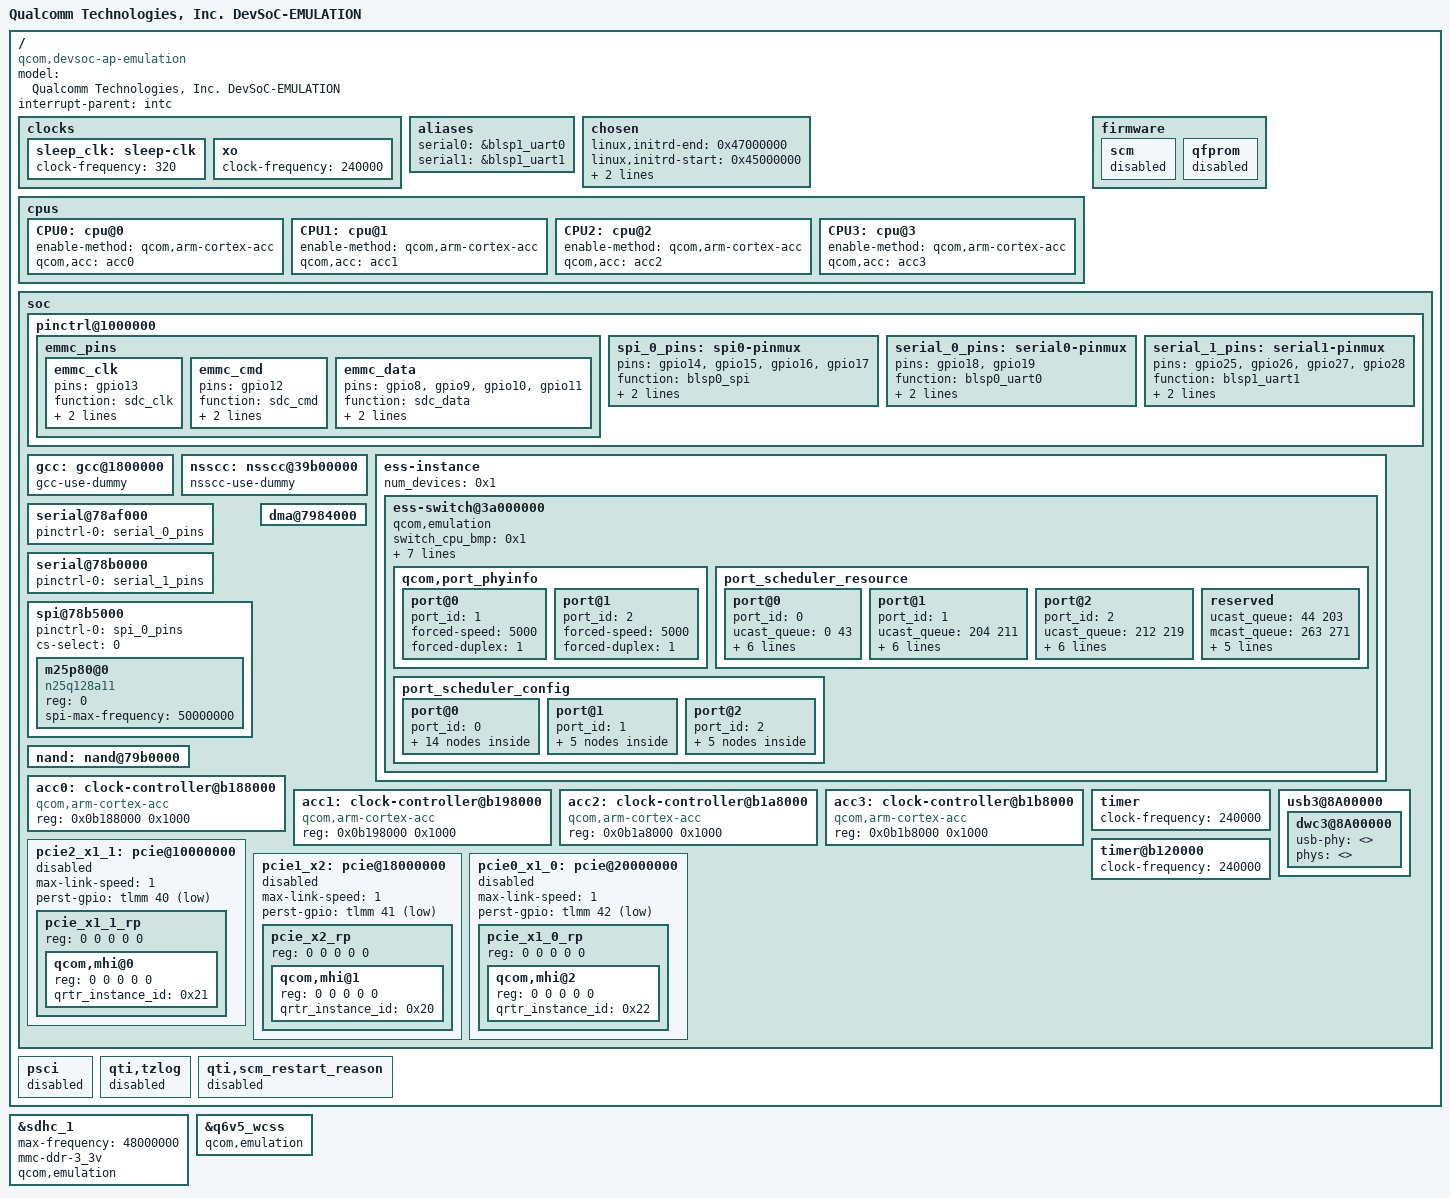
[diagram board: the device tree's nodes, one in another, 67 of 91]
// SPDX-License-Identifier: (GPL-2.0+ OR BSD-3-Clause)
/*
 * Dev SoC Emulation board device tree source
 *
 * Copyright (c) 2020-2021 The Linux Foundation. All rights reserved.
 * Copyright (c) 2022 Qualcomm Innovation Center, Inc. All rights reserved.
 */

/dts-v1/;

#include "devsoc.dtsi"
#include "devsoc-default-memory.dtsi"

/ {
	#address-cells = <0x2>;
	#size-cells = <0x2>;
	model = "Qualcomm Technologies, Inc. DevSoC-EMULATION";
	compatible = "qcom,devsoc-ap-emulation", "qcom,devsoc";
	interrupt-parent = <&intc>;

	clocks {
		sleep_clk: sleep-clk {
			clock-frequency = <320>;
		};

		xo: xo {
			clock-frequency = <240000>;
		};
	};

	aliases {
		serial0 = &blsp1_uart0;
		serial1 = &blsp1_uart1;
	};

	chosen {
		linux,initrd-end = <0x47000000>;
		linux,initrd-start = <0x45000000>;
		bootargs = "root=/dev/ram0 rw init=/init";
		stdout-path = "serial0";
	};

	cpus: cpus {
		CPU0: cpu@0 {
			enable-method = "qcom,arm-cortex-acc";
			qcom,acc = <&acc0>;
		};

		CPU1: cpu@1 {
			enable-method = "qcom,arm-cortex-acc";
			qcom,acc = <&acc1>;
		};

		CPU2: cpu@2 {
			enable-method = "qcom,arm-cortex-acc";
			qcom,acc = <&acc2>;
		};

		CPU3: cpu@3 {
			enable-method = "qcom,arm-cortex-acc";
			qcom,acc = <&acc3>;
		};
	};

	firmware {
		scm {
			status = "disabled";
		};

		qfprom {
			status = "disabled";
		};
	};

	soc {
		pinctrl@1000000 {
			emmc_pins: emmc_pins {
				emmc_clk {
					pins = "gpio13";
					function = "sdc_clk";
					drive-strength = <8>;
					bias-disable;
				};
				emmc_cmd {
					pins = "gpio12";
					function = "sdc_cmd";
					drive-strength = <8>;
					bias-pull-up;
				};
				emmc_data {
					pins = "gpio8", "gpio9", "gpio10",
						"gpio11";
					function = "sdc_data";
					drive-strength = <8>;
					bias-pull-up;
				};
			};

			spi_0_pins: spi0-pinmux {
				pins = "gpio14", "gpio15", "gpio16", "gpio17";
				function = "blsp0_spi";
				drive-strength = <2>;
				bias-disable;
			};

			serial_0_pins: serial0-pinmux {
				pins = "gpio18", "gpio19";
				function = "blsp0_uart0";
				drive-strength = <8>;
				bias-pull-down;
			};

			serial_1_pins: serial1-pinmux {
				pins = "gpio25", "gpio26", "gpio27", "gpio28";
				function = "blsp1_uart1";
				drive-strength = <8>;
				bias-pull-down;
			};
		};

		gcc: gcc@1800000 {
			gcc-use-dummy;
		};

		nsscc: nsscc@39b00000 {
			nsscc-use-dummy;
		};

		ess-instance {
			num_devices = <0x1>;
			ess-switch@3a000000 {
				qcom,emulation; /* RUMI ENV */
				switch_cpu_bmp = <0x1>;  /* cpu port bitmap */
				switch_lan_bmp = <0x4>; /* lan port bitmap */
				switch_wan_bmp = <0x2>; /* wan port bitmap */
				switch_mac_mode = <0xd>; /* mac mode for uniphy instance0*/
				switch_mac_mode1 = <0xd>; /* mac mode for uniphy instance1*/
				switch_mac_mode2 = <0xff>; /* mac mode for uniphy instance2*/
				bm_tick_mode = <0>; /* bm tick mode */
				tm_tick_mode = <0>; /* tm tick mode */

				qcom,port_phyinfo {
					port@0 {
						port_id = <1>;
						forced-speed = <5000>;
						forced-duplex = <1>;
					};
					port@1 {
						port_id = <2>;
						forced-speed = <5000>;
						forced-duplex = <1>;
					};
				};
				port_scheduler_resource {
					port@0 {
						port_id = <0>;
						ucast_queue = <0 43>;
						mcast_queue = <256 262>;
						l0sp = <0 6>;
						l0cdrr = <0 27>;
						l0edrr = <0 27>;
						l1cdrr = <0 0>;
						l1edrr = <0 0>;
					};
					port@1 {
						port_id = <1>;
						ucast_queue = <204 211>;
						mcast_queue = <272 275>;
						l0sp = <51 52>;
						l0cdrr = <108 115>;
						l0edrr = <108 115>;
						l1cdrr = <23 24>;
						l1edrr = <23 24>;
					};
					port@2 {
						port_id = <2>;
						ucast_queue = <212 219>;
						mcast_queue = <276 279>;
						l0sp = <53 54>;
						l0cdrr = <116 123>;
						l0edrr = <116 123>;
						l1cdrr = <25 26>;
						l1edrr = <25 26>;
					};
					reserved {
						ucast_queue = <44 203>;
						mcast_queue = <263 271>;
						l0sp = <7 50>;
						l0cdrr = <28 107>;
						l0edrr = <28 107>;
						l1cdrr = <1 22>;
						l1edrr = <1 22>;
					};
				};
				port_scheduler_config {
					port@0 {
						port_id = <0>;
						l1scheduler {
							group@0 {
								/* L0 SP */
								sp = <0 1 2 3 4 5 6>;
								/* cpri cdrr epri edrr */
								cfg = <0 0 0 0>;
							};
						};
						l0scheduler {
							group@0 {
								/* unicast queue */
								ucast_queue = <0>;
								ucast_loop_pri = <4>;
								/* multicast queue */
								mcast_queue = <256>;
								/* sp cpri cdrr epri edrr */
								cfg = <0 0 0 0 0>;
							};
							group@1 {
								ucast_queue = <4>;
								ucast_loop_pri = <4>;
								cfg = <0 0 0 0 0>;
							};
							group@2 {
								ucast_queue = <8>;
								ucast_loop_pri = <4>;
								mcast_queue = <257>;
								cfg = <1 0 4 0 4>;
							};
							group@3 {
								ucast_queue = <12>;
								ucast_loop_pri = <4>;
								cfg = <1 0 4 0 4>;
							};
							group@4 {
								ucast_queue = <16>;
								ucast_loop_pri = <4>;
								mcast_queue = <258>;
								cfg = <2 0 8 0 8>;
							};
							group@5 {
								ucast_queue = <20>;
								ucast_loop_pri = <4>;
								cfg = <2 0 8 0 8>;
							};
							group@6 {
								ucast_queue = <24>;
								ucast_loop_pri = <4>;
								mcast_queue = <259>;
								cfg = <3 0 12 0 12>;
							};
							group@7 {
								ucast_queue = <28>;
								ucast_loop_pri = <4>;
								cfg = <3 0 12 0 12>;
							};
							group@8 {
								ucast_queue = <32>;
								ucast_loop_pri = <4>;
								mcast_queue = <260>;
								cfg = <4 0 16 0 16>;
							};
							group@9 {
								ucast_queue = <36>;
								ucast_loop_pri = <4>;
								mcast_queue = <261>;
								cfg = <5 0 20 0 20>;
							};
							group@10 {
								ucast_queue = <40>;
								ucast_loop_pri = <4>;
								mcast_queue = <262>;
								cfg = <6 0 24 0 24>;
							};
						};
					};
					port@1 {
						port_id = <1>;
						l1scheduler {
							group@0 {
								sp = <51>;
								cfg = <0 23 0 23>;
							};
							group@1 {
								sp = <52>;
								cfg = <1 24 1 24>;
							};
						};
						l0scheduler {
							group@0 {
								ucast_queue = <204>;
								ucast_loop_pri = <8>;
								/* max priority per SP */
								ucast_max_pri = <4>;
								mcast_queue = <272>;
								mcast_loop_pri = <4>;
								cfg = <51 0 108 0 108>;
							};
						};
					};
					port@2 {
						port_id = <2>;
						l1scheduler {
							group@0 {
								sp = <53>;
								cfg = <0 25 0 25>;
							};
							group@1 {
								sp = <54>;
								cfg = <1 26 1 26>;
							};
						};
						l0scheduler {
							group@0 {
								ucast_queue = <212>;
								ucast_loop_pri = <8>;
								ucast_max_pri = <4>;
								mcast_queue = <276>;
								mcast_loop_pri = <4>;
								cfg = <53 0 116 0 116>;
							};
						};
					};
				};
			};
		};

		serial@78af000 {
			pinctrl-0 = <&serial_0_pins>;
			pinctrl-names = "default";
			status = "ok";
		};

		serial@78b0000 {
			pinctrl-0 = <&serial_1_pins>;
			pinctrl-names = "default";
			status = "ok";
		};

		spi@78b5000 {
			pinctrl-0 = <&spi_0_pins>;
			pinctrl-names = "default";
			cs-select = <0>;
			status = "ok";

			m25p80@0 {
				compatible = "n25q128a11";
				#address-cells = <1>;
				#size-cells = <1>;
				reg = <0>;
				spi-max-frequency = <50000000>;
			};
		};

		dma@7984000 {
			status = "ok";
		};

		nand: nand@79b0000 {
			status = "ok";
		};

		acc0: clock-controller@b188000 {
			compatible = "qcom,arm-cortex-acc";
			reg = <0x0b188000 0x1000>;
		};

		acc1: clock-controller@b198000 {
			compatible = "qcom,arm-cortex-acc";
			reg = <0x0b198000 0x1000>;
		};

		acc2:clock-controller@b1a8000 {
			compatible = "qcom,arm-cortex-acc";
			reg = <0x0b1a8000 0x1000>;
		};

		acc3:clock-controller@b1b8000 {
			compatible = "qcom,arm-cortex-acc";
			reg = <0x0b1b8000 0x1000>;
		};

		/*Timer freq for rumi = timer freq / 100*/
		timer {
			clock-frequency = <240000>;
		};

		timer@b120000 {
			clock-frequency = <240000>;
		};

		usb3@8A00000 {
			status = "ok";

			dwc3@8A00000 {
				usb-phy = <>;
				phys = <>;
				phy-names = "";
			};
		};

		pcie2_x1_1: pcie@10000000 {
			max-link-speed = <1>;
			perst-gpio = <&tlmm 40 GPIO_ACTIVE_LOW>;
			status = "disabled";
			pcie_x1_1_rp {
				reg = <0 0 0 0 0>;

				qcom,mhi@0 {
					reg = <0 0 0 0 0>;
					qrtr_instance_id = <0x21>;
				};
			};
		};

		pcie1_x2: pcie@18000000 {
			max-link-speed = <1>;
			perst-gpio = <&tlmm 41 GPIO_ACTIVE_LOW>;
			status = "disabled";
			pcie_x2_rp {
				reg = <0 0 0 0 0>;

				qcom,mhi@1 {
					reg = <0 0 0 0 0>;
					qrtr_instance_id = <0x20>;
				};
			};
		};

		pcie0_x1_0: pcie@20000000 {
			max-link-speed = <1>;
			perst-gpio = <&tlmm 42 GPIO_ACTIVE_LOW>;
			status = "disabled";
			pcie_x1_0_rp {
				reg = <0 0 0 0 0>;

				qcom,mhi@2 {
					reg = <0 0 0 0 0>;
					qrtr_instance_id = <0x22>;
				};
			};
		};
	};

	psci {
		status = "disabled";
	};

	qti,tzlog {
		status = "disabled";
	};

	qti,scm_restart_reason {
		status = "disabled";
	};

};

&sdhc_1 {
	/* over-ride the frequency to 48Mhz for emulation platform */
	max-frequency = <48000000>;
	/* Force 3.3V, because only that will support on emulation platform */
	mmc-ddr-3_3v;
	qcom,emulation;
        status = "ok";
};

&q6v5_wcss {
	qcom,emulation;
};
